# ATA6617C device description
Architecture: AVR8; Family: tinyAVR
Registers are 8-bit, access not given, no defined reset value unless marked. A register's access mark holds for its fields unless they carry their own. Offsets are from the block's base; [hi:lo] are bit positions; 'fields as' and 'values as' point back to an identical list.

## ANALOG_COMPARATOR
Instances: ANALOG_COMPARATOR 0x00
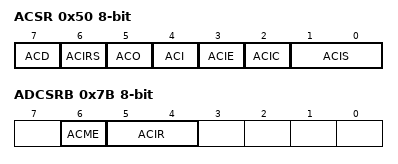
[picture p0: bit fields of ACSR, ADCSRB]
0x50 ACSR — Analog Comparator Control And Status Register
  [7] ACD — Analog Comparator Disable
  [6] ACIRS — Analog Comparator Internal Reference Select
  [5] ACO — Analog Compare Output
  [4] ACI — Analog Comparator Interrupt Flag
  [3] ACIE — Analog Comparator Interrupt Enable
  [2] ACIC — Analog Comparator Input Capture Enable
  [1:0] ACIS — Analog Comparator Interrupt Mode Select bits
    0=Interrupt on Toggle; 2=Interrupt on Falling Edge; 3=Interrupt on Rising Edge
0x7B ADCSRB — Analog Comparator & ADC Control and Status Register B (Shared with AD_CONVERTER IO_MODULE)
  [6] ACME — Analog Comparator Multiplexer Enable
  [5:4] ACIR — Analog Comparator Internal Voltage Reference Select Bits

## EXTERNAL_INTERRUPT
Instances: EXTERNAL_INTERRUPT 0x00
0x3B PCIFR — Pin Change Interrupt Flag Register
  [1:0] PCIF — Pin Change Interrupt Flags
0x3C EIFR — External Interrupt Flag Register
  [1:0] INTF — External Interrupt Flags
0x3D EIMSK — External Interrupt Mask Register
  [1:0] INT — External Interrupt Request 1 Enable
0x68 PCICR — Pin Change Interrupt Control Register
  [1:0] PCIE — Pin Change Interrupt Enable on any PCINT14..8 pin
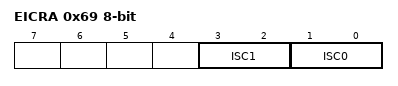
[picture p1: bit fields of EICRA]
0x69 EICRA — External Interrupt Control Register
  [3:2] ISC1 — External Interrupt Sense Control 1 Bits
    0=Low Level of INTX; 1=Any Logical Change in INTX; 2=Falling Edge of INTX; 3=Rising Edge of INTX
  [1:0] ISC0 — External Interrupt Sense Control 0 Bits
    values as ISC1
0x6B PCMSK0 — Pin Change Mask Register 0
  [7:0] PCINT — Pin Change Enable Masks
0x6C PCMSK1 — Pin Change Mask Register 1
  [7:0] PCINT (bit 8 of the value upward) — Pin Change Enable Masks

## BOOT_LOAD
Instances: BOOT_LOAD 0x00
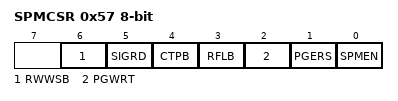
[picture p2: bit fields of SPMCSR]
0x57 SPMCSR — Store Program Memory Control Register
  [6] RWWSB — Read While Write Section Busy
  [5] SIGRD — Signature Row Read
  [4] CTPB — Clear Temporary Page Buffer
  [3] RFLB — Read Fuse and Lock Bits
  [2] PGWRT — Page Write
  [1] PGERS — Page Erase
  [0] SPMEN — Store Program Memory Enable

## CPU
Instances: CPU 0x00
Parameters: CORE_VERSION=V2, NEW_INSTRUCTIONS=lpm rd,z+
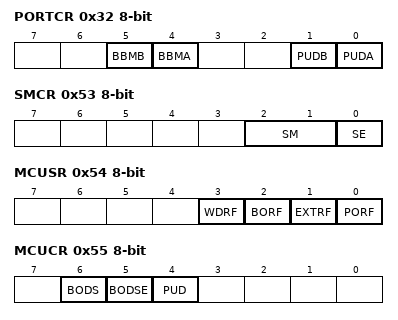
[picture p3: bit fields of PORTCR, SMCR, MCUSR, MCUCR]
0x32 PORTCR — Port Control Register
  [5] BBMB, [4] BBMA, [1] PUDB, [0] PUDA
0x3E GPIOR0 — General purpose register 0
  [7:0] GPIOR0 — General Purpose IO register 0 Bits
0x4A GPIOR1 — General Purpose register 1
  [7:0] GPIOR1 — General Purpose IO register 1 Bits
0x4B GPIOR2 — General Purpose IO register 2
  [7:0] GPIOR2 — General Purpose IO register 2 Bits
0x51 DWDR — DebugWire data register
  [7:0] DWDR — DebugWire data register bits
0x53 SMCR — Sleep Mode Control Register
  [2:1] SM — Sleep Mode Select Bits
    0=IDLE; 1=ADC (ADC Noise Reduction (If Available)); 2=PDOWN (Power Down)
  [0] SE — Sleep Enable
0x54 MCUSR — MCU Status register
  [3] WDRF — Watchdog Reset Flag
  [2] BORF — Brown-out Reset Flag
  [1] EXTRF — External Reset Flag
  [0] PORF — Power-On Reset Flag
0x55 MCUCR — MCU Control Register
  [6] BODS — BOD Sleep
  [5] BODSE — BOD Sleep Enable
  [4] PUD — Pull-up Disable
0x5D SP 16-bit bits used 10:0 — Stack Pointer Bytes
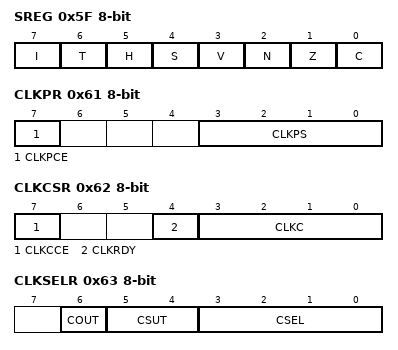
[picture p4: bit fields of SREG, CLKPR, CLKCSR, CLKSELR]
0x5F SREG — Status Register
  [7] I — Global Interrupt Enable
  [6] T — Bit Copy Storage
  [5] H — Half Carry Flag
  [4] S — Sign Bit
  [3] V — Two's Complement Overflow Flag
  [2] N — Negative Flag
  [1] Z — Zero Flag
  [0] C — Carry Flag
0x61 CLKPR — Clock Prescale Register
  [7] CLKPCE — Clock Prescaler Change Enable
  [3:0] CLKPS — Clock Prescaler Select Bits
    0=1; 1=2; 2=4; 3=8; 4=16; 5=32; 6=64; 7=128; 8=256
0x62 CLKCSR — Clock Control & Status Register
  [7] CLKCCE — Clock Control Change Enable
  [4] CLKRDY — Clock Ready Flag
  [3:0] CLKC — Clock Control bits
    0=No Command; 1=Disable Clock Source; 2=Enable Clock Source; 3=Request for Clock Availability; 4=Clock Source Switch; 5=Recovery System Clock Source Code; 6=Enable Watchdog in Automatic Reload Mode; 7=CKOUT Command; 8=From 0x08 up to 0x0F: No command
0x63 CLKSELR — Clock Selection Register
  [6] COUT — Clock Out - CKOUT fuse substitution
  [5:4] CSUT — Clock Start-up Time bit 1 - SUT1 fuse substitution
  [3:0] CSEL — Clock Source Select bit 3 - CKSEL3 fuse substitution
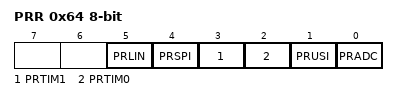
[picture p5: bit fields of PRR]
0x64 PRR — Power Reduction Register
  [5] PRLIN — Power Reduction LINUART
  [4] PRSPI — Power Reduction SPI
  [3] PRTIM1 — Power Reduction Timer/Counter1
  [2] PRTIM0 — Power Reduction Timer/Counter0
  [1] PRUSI — Power Reduction USI
  [0] PRADC — Power Reduction ADC
0x66 OSCCAL — Oscillator Calibration Register
  [7:0] CAL — Oscillator Calibration Register bits
  [7:0] OSCCAL — Oscillator Calibration
Value list OSCCAL_VALUE_ADDRESSES: 0=8_0_MHz
